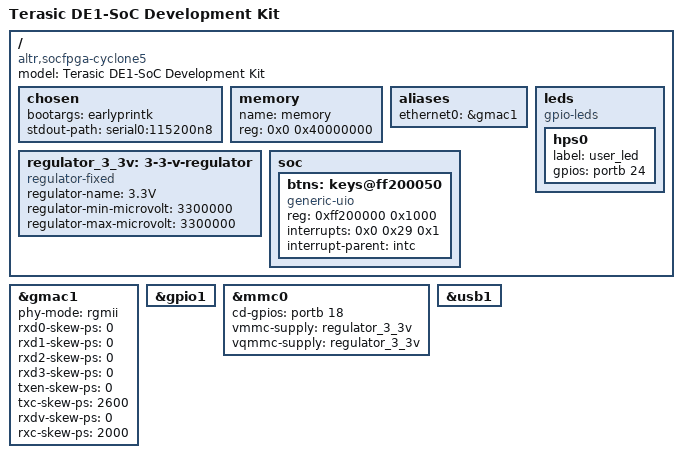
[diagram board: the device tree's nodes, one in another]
// SPDX-License-Identifier: GPL-2.0+
/*
 *  Copyright (C) 2012 Altera Corporation <www.altera.com>
 *  Copyright (C) 2017 Gerhard Engleder <engleder.gerhard@gmail.com>
 *
 * This program is free software; you can redistribute it and/or modify
 * it under the terms of the GNU General Public License as published by
 * the Free Software Foundation; either version 2 of the License, or
 * (at your option) any later version.
 *
 * This program is distributed in the hope that it will be useful,
 * but WITHOUT ANY WARRANTY; without even the implied warranty of
 * MERCHANTABILITY or FITNESS FOR A PARTICULAR PURPOSE.  See the
 * GNU General Public License for more details.
 *
 * You should have received a copy of the GNU General Public License
 * along with this program.  If not, see <http://www.gnu.org/licenses/>.
 */

#include "socfpga_cyclone5.dtsi"

/ {
	model = "Terasic DE1-SoC Development Kit";
	compatible = "altr,socfpga-cyclone5", "altr,socfpga";

	chosen {
		bootargs = "earlyprintk";
		stdout-path = "serial0:115200n8";
	};

	memory {
		name = "memory";
		device_type = "memory";
		reg = <0x0 0x40000000>; /* 1GB */
	};

	aliases {
		/* This allows the ethaddr uboot environment variable
		 * to be added to the gmac1 device tree blob
		 */
		ethernet0 = &gmac1;
	};

	leds {
		compatible = "gpio-leds";
		hps0 {
			label = "user_led";
			gpios = <&portb 24 0>;
		};
	};

	regulator_3_3v: 3-3-v-regulator {
		compatible = "regulator-fixed";
		regulator-name = "3.3V";
		regulator-min-microvolt = <3300000>;
		regulator-max-microvolt = <3300000>;
	};

	soc {
		btns: keys@ff200050 {
			compatible = "generic-uio";
			reg = <0xff200000 0x1000>;
			interrupts= <0x0 0x29 0x1>;
			interrupt-parent = <&intc>;
		};
	};

};

&gmac1 {
	status = "okay";
	phy-mode = "rgmii";

	rxd0-skew-ps = <0>;
	rxd1-skew-ps = <0>;
	rxd2-skew-ps = <0>;
	rxd3-skew-ps = <0>;
	txen-skew-ps = <0>;
	txc-skew-ps = <2600>;
	rxdv-skew-ps = <0>;
	rxc-skew-ps = <2000>;
};

&gpio1 {
	status = "okay";
};

&mmc0 {
	cd-gpios = <&portb 18 0>;
	vmmc-supply = <&regulator_3_3v>;
	vqmmc-supply = <&regulator_3_3v>;
	status = "okay";
};

&usb1 {
	status = "okay";
};
